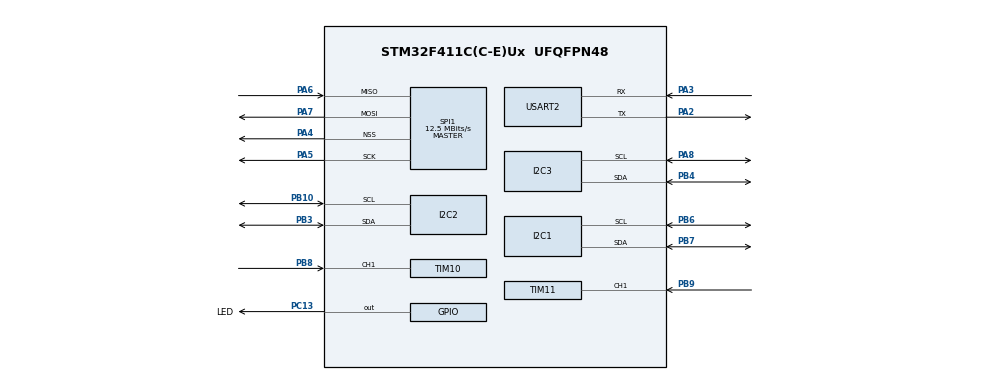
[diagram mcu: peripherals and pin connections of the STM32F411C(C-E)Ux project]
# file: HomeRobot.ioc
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I2C1.I2C_Mode=I2C_Fast
I2C2.I2C_Mode=I2C_Fast
I2C3.I2C_Mode=I2C_Fast
Mcu.Family=STM32F4
Mcu.Name=STM32F411C(C-E)Ux
Mcu.Package=UFQFPN48
NVIC.I2C1_ER_IRQn=true\:0\:0\:false\:false\:true\:true\:true\:true
NVIC.I2C1_EV_IRQn=true\:0\:0\:false\:false\:true\:true\:true\:true
NVIC.I2C2_ER_IRQn=true\:0\:0\:false\:false\:true\:true\:true\:true
NVIC.I2C2_EV_IRQn=true\:0\:0\:false\:false\:true\:true\:true\:true
NVIC.I2C3_ER_IRQn=true\:0\:0\:false\:false\:true\:true\:true\:true
NVIC.I2C3_EV_IRQn=true\:0\:0\:false\:false\:true\:true\:true\:true
NVIC.PriorityGroup=NVIC_PRIORITYGROUP_4
NVIC.SPI1_IRQn=true\:0\:0\:false\:false\:true\:true\:true\:true
NVIC.TIM1_TRG_COM_TIM11_IRQn=true\:0\:0\:false\:false\:true\:true\:true\:true
NVIC.TIM1_UP_TIM10_IRQn=true\:0\:0\:false\:false\:true\:true\:true\:true
NVIC.USART2_IRQn=true\:0\:0\:false\:false\:true\:true\:true\:true
PA13.Mode=Serial_Wire
PA13.Signal=SYS_JTMS-SWDIO
PA14.Mode=Serial_Wire
PA14.Signal=SYS_JTCK-SWCLK
PA2.Mode=Asynchronous
PA2.Signal=USART2_TX
PA3.Mode=Asynchronous
PA3.Signal=USART2_RX
PA4.Mode=NSS_Signal_Hard_Output
PA4.Signal=SPI1_NSS
PA5.Mode=Full_Duplex_Master
PA5.Signal=SPI1_SCK
PA6.Mode=Full_Duplex_Master
PA6.Signal=SPI1_MISO
PA7.Mode=Full_Duplex_Master
PA7.Signal=SPI1_MOSI
PA8.Mode=I2C
PA8.Signal=I2C3_SCL
PB10.Mode=I2C
PB10.Signal=I2C2_SCL
PB3.Mode=I2C
PB3.Signal=I2C2_SDA
PB4.Mode=I2C
PB4.Signal=I2C3_SDA
PB6.Mode=I2C
PB6.Signal=I2C1_SCL
PB7.Mode=I2C
PB7.Signal=I2C1_SDA
PB8.Signal=S_TIM10_CH1
PB9.Signal=S_TIM11_CH1
PC13-ANTI_TAMP.GPIO_Label=LED
PC13-ANTI_TAMP.GPIO_ModeDefaultOutputPP=GPIO_MODE_OUTPUT_OD
PC13-ANTI_TAMP.GPIO_PuPd=GPIO_NOPULL
PC13-ANTI_TAMP.Signal=GPIO_Output
PC14-OSC32_IN.Mode=LSE-External-Oscillator
PC14-OSC32_IN.Signal=RCC_OSC32_IN
PC15-OSC32_OUT.Mode=LSE-External-Oscillator
PC15-OSC32_OUT.Signal=RCC_OSC32_OUT
PH0\ -\ OSC_IN.Mode=HSE-External-Oscillator
PH0\ -\ OSC_IN.Signal=RCC_OSC_IN
PH1\ -\ OSC_OUT.Mode=HSE-External-Oscillator
PH1\ -\ OSC_OUT.Signal=RCC_OSC_OUT
ProjectManager.HeapSize=0x200
ProjectManager.StackSize=0x400
ProjectManager.TargetToolchain=STM32CubeIDE
RCC.48MHZClocksFreq_Value=50000000
RCC.AHBFreq_Value=100000000
RCC.APB1CLKDivider=RCC_HCLK_DIV2
RCC.APB1Freq_Value=50000000
RCC.APB1TimFreq_Value=100000000
RCC.APB2Freq_Value=100000000
RCC.APB2TimFreq_Value=100000000
RCC.CortexFreq_Value=100000000
RCC.EnbaleCSS=true
RCC.HCLKFreq_Value=100000000
RCC.HSE_VALUE=25000000
RCC.HSI_VALUE=16000000
RCC.PLLM=12
RCC.PLLN=96
RCC.PLLSourceVirtual=RCC_PLLSOURCE_HSE
RCC.RCC_RTC_Clock_Source=RCC_RTCCLKSOURCE_LSI
RCC.RCC_RTC_Clock_SourceVirtual=RCC_RTCCLKSOURCE_LSI
RCC.SYSCLKFreq_VALUE=100000000
RCC.SYSCLKSource=RCC_SYSCLKSOURCE_PLLCLK
RCC.VCOOutputFreq_Value=200000000
RTC.Format=RTC_FORMAT_BIN
SH.S_TIM10_CH1.0=TIM10_CH1,Input_Capture1_from_TI1
SH.S_TIM11_CH1.0=TIM11_CH1,Input_Capture1_from_TI1
SPI1.BaudRatePrescaler=SPI_BAUDRATEPRESCALER_8
SPI1.CalculateBaudRate=12.5 MBits/s
SPI1.Direction=SPI_DIRECTION_2LINES
SPI1.Mode=SPI_MODE_MASTER
SPI1.VirtualNSS=VM_NSSHARD
SPI1.VirtualType=VM_MASTER
TIM10.Channel=TIM_CHANNEL_1
TIM10.ICFilter_CH1=4
TIM10.Prescaler=999
TIM11.Channel=TIM_CHANNEL_1
TIM11.ICFilter_CH1=4
TIM11.Prescaler=999
USART2.VirtualMode=VM_ASYNC
VP_CRC_VS_CRC.Mode=CRC_Activate
VP_RTC_VS_RTC_Activate.Mode=RTC_Enabled
VP_RTC_VS_RTC_Calendar.Mode=RTC_Calendar
VP_TIM10_VS_ClockSourceINT.Mode=Enable_Timer
VP_TIM11_VS_ClockSourceINT.Mode=Enable_Timer
board=custom

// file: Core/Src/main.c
/* USER CODE BEGIN Header */
/**
  ******************************************************************************
  * @file           : main.c
  * @brief          : Main program body
  ******************************************************************************
  * @attention
  *
  * Copyright (c) 2023 STMicroelectronics.
  * All rights reserved.
  *
  * This software is licensed under terms that can be found in the LICENSE file
  * in the root directory of this software component.
  * If no LICENSE file comes with this software, it is provided AS-IS.
  *
  ******************************************************************************
  */
/* USER CODE END Header */
#include "main.h"
#include "crc.h"
#include "i2c.h"
#include "rtc.h"
#include "spi.h"
#include "tim.h"
#include "usart.h"
#include "gpio.h"

void SystemClock_Config(void);

int main(void)
{

  /* MCU Configuration--------------------------------------------------------*/

  /* Reset of all peripherals, Initializes the Flash interface and the Systick. */
  LL_APB2_GRP1_EnableClock(LL_APB2_GRP1_PERIPH_SYSCFG);
  LL_APB1_GRP1_EnableClock(LL_APB1_GRP1_PERIPH_PWR);

  /* System interrupt init*/
  NVIC_SetPriorityGrouping(NVIC_PRIORITYGROUP_4);

  /* SysTick_IRQn interrupt configuration */
  NVIC_SetPriority(SysTick_IRQn, NVIC_EncodePriority(NVIC_GetPriorityGrouping(),15, 0));

  /* Configure the system clock */
  SystemClock_Config();

  /* Initialize all configured peripherals */
  MX_GPIO_Init();
  MX_CRC_Init();
  MX_RTC_Init();
  MX_I2C1_Init();
  MX_I2C2_Init();
  MX_I2C3_Init();
  MX_SPI1_Init();
  MX_USART2_UART_Init();
  MX_TIM10_Init();
  MX_TIM11_Init();

  /* Infinite loop */
  /* USER CODE BEGIN WHILE */
  while (1)
  {
	  LL_GPIO_TogglePin(LED_GPIO_Port, LED_Pin);
	  LL_mDelay(1000);
    /* USER CODE END WHILE */

  }
}

void SystemClock_Config(void)
{
  LL_FLASH_SetLatency(LL_FLASH_LATENCY_3);
  while(LL_FLASH_GetLatency()!= LL_FLASH_LATENCY_3)
  {
  }
  LL_PWR_SetRegulVoltageScaling(LL_PWR_REGU_VOLTAGE_SCALE1);
  LL_RCC_HSE_Enable();

   /* Wait till HSE is ready */
  while(LL_RCC_HSE_IsReady() != 1)
  {

  }
  LL_RCC_LSI_Enable();

   /* Wait till LSI is ready */
  while(LL_RCC_LSI_IsReady() != 1)
  {

  }
  LL_PWR_EnableBkUpAccess();
  LL_RCC_HSE_EnableCSS();
  LL_RCC_PLL_ConfigDomain_SYS(LL_RCC_PLLSOURCE_HSE, LL_RCC_PLLM_DIV_12, 96, LL_RCC_PLLP_DIV_2);
  LL_RCC_PLL_Enable();

   /* Wait till PLL is ready */
  while(LL_RCC_PLL_IsReady() != 1)
  {

  }
  LL_RCC_SetAHBPrescaler(LL_RCC_SYSCLK_DIV_1);
  LL_RCC_SetAPB1Prescaler(LL_RCC_APB1_DIV_2);
  LL_RCC_SetAPB2Prescaler(LL_RCC_APB2_DIV_1);
  LL_RCC_SetSysClkSource(LL_RCC_SYS_CLKSOURCE_PLL);

   /* Wait till System clock is ready */
  while(LL_RCC_GetSysClkSource() != LL_RCC_SYS_CLKSOURCE_STATUS_PLL)
  {

  }
  LL_Init1msTick(100000000);
  LL_SetSystemCoreClock(100000000);
  LL_RCC_SetTIMPrescaler(LL_RCC_TIM_PRESCALER_TWICE);
}

void Error_Handler(void)
{
  __disable_irq();
  while (1)
  {
  }
}
